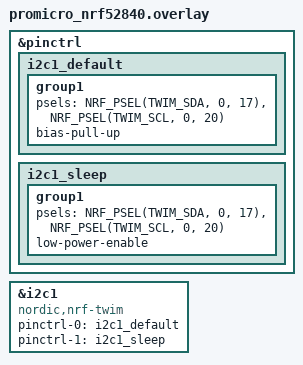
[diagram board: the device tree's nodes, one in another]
#include <dt-bindings/pinctrl/nrf-pinctrl.h>

&pinctrl {
    i2c1_default: i2c1_default {
        group1 {
            psels = <NRF_PSEL(TWIM_SDA, 0, 17)>,
                    <NRF_PSEL(TWIM_SCL, 0, 20)>;
            bias-pull-up;
        };
    };
    i2c1_sleep: i2c1_sleep {
        group1 {
            psels = <NRF_PSEL(TWIM_SDA, 0, 17)>,
                    <NRF_PSEL(TWIM_SCL, 0, 20)>;
            low-power-enable;
        };
    };
};

pro_micro_i2c: &i2c1 {
    compatible = "nordic,nrf-twim";
    status = "okay";
    pinctrl-0 = <&i2c1_default>;
    pinctrl-1 = <&i2c1_sleep>;
    pinctrl-names = "default", "sleep";
};
